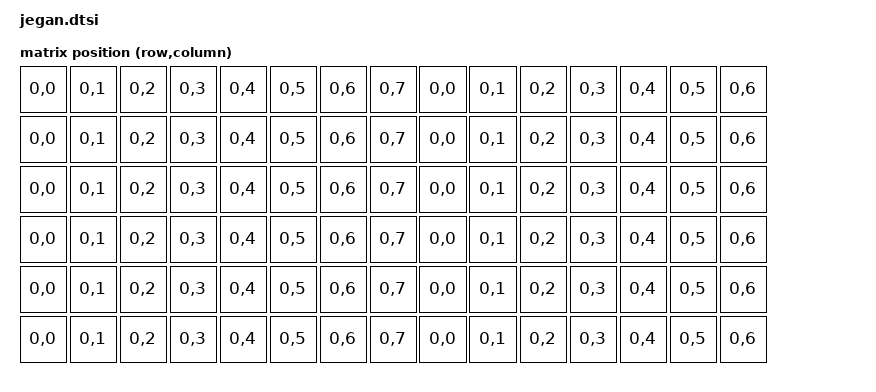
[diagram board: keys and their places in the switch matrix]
// This file was generated from a template. Edit it to match your keyboard.
// See https://zmk.dev/docs/development/hardware-integration/new-shield for more
// instructions.

#include <dt-bindings/zmk/matrix_transform.h>
#include <dt-bindings/led/led.h>

#include "jegan-layouts.dtsi"
#include "jegan-pinctrl.dtsi"

/ {
    chosen {
        zmk,physical-layout = &default_layout;
        zmk,kscan = &kscan;
        zmk,underglow = &led_strip;
    };

    kscan: kscan {
        // If the hardware does not use a switch matrix, change this to the
        // appropriate driver and update the properties below to match.
        // See https://zmk.dev/docs/config/kscan for supported key scan drivers.
        compatible = "zmk,kscan-gpio-matrix";
        // Set this to "col2row" or "row2col" to match the hardware. If using
        // "row2col", change the col-gpios in the _left.overlay and _right.overlay
        // files to (GPIO_ACTIVE_HIGH | GPIO_PULL_DOWN) and the row-gpios here to
        // GPIO_ACTIVE_HIGH.
        diode-direction = "col2row";
        wakeup-source;
    };

    default_transform: default_transform {
        // See https://zmk.dev/docs/development/hardware-integration/new-shield#matrix-transform
        // for how to configure this
        compatible = "zmk,matrix-transform";
        columns = <15>;
        rows = <6>;

        map = <
            RC(0, 0) RC(0, 1) RC(0, 2) RC(0, 3) RC(0, 4) RC(0, 5) RC(0, 6) RC(0, 7) RC(0, 0) RC(0, 1) RC(0, 2) RC(0, 3) RC(0, 4) RC(0, 5) RC(0, 6)
            RC(0, 0) RC(0, 1) RC(0, 2) RC(0, 3) RC(0, 4) RC(0, 5) RC(0, 6) RC(0, 7) RC(0, 0) RC(0, 1) RC(0, 2) RC(0, 3) RC(0, 4) RC(0, 5) RC(0, 6)
            RC(0, 0) RC(0, 1) RC(0, 2) RC(0, 3) RC(0, 4) RC(0, 5) RC(0, 6) RC(0, 7) RC(0, 0) RC(0, 1) RC(0, 2) RC(0, 3) RC(0, 4) RC(0, 5) RC(0, 6)
            RC(0, 0) RC(0, 1) RC(0, 2) RC(0, 3) RC(0, 4) RC(0, 5) RC(0, 6) RC(0, 7) RC(0, 0) RC(0, 1) RC(0, 2) RC(0, 3) RC(0, 4) RC(0, 5) RC(0, 6)
            RC(0, 0) RC(0, 1) RC(0, 2) RC(0, 3) RC(0, 4) RC(0, 5) RC(0, 6) RC(0, 7) RC(0, 0) RC(0, 1) RC(0, 2) RC(0, 3) RC(0, 4) RC(0, 5) RC(0, 6)
            RC(0, 0) RC(0, 1) RC(0, 2) RC(0, 3) RC(0, 4) RC(0, 5) RC(0, 6) RC(0, 7) RC(0, 0) RC(0, 1) RC(0, 2) RC(0, 3) RC(0, 4) RC(0, 5) RC(0, 6)
        >;
    };
};
